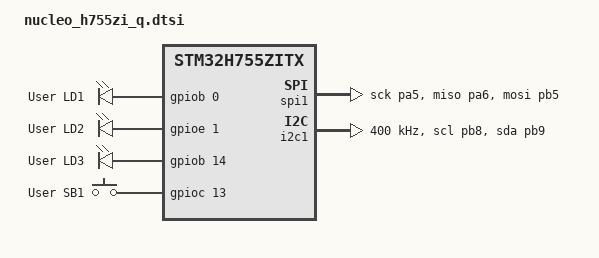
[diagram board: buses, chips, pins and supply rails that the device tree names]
/*
 * Copyright (c) 2024 S&C Electric Company <Michael.Banducci@sandc.com>
 *
 * SPDX-License-Identifier: Apache-2.0
 */

#include <st/h7/stm32h755zitx-pinctrl.dtsi>
#include "arduino_r3_connector.dtsi"
#include <zephyr/dt-bindings/input/input-event-codes.h>

/ {
	leds: leds {
		compatible = "gpio-leds";

		green_led: led_1 {
			gpios = <&gpiob 0 GPIO_ACTIVE_HIGH>;
			label = "User LD1";
		};

		yellow_led: led_2 {
			gpios = <&gpioe 1 GPIO_ACTIVE_HIGH>;
			label = "User LD2";
		};

		red_led: led_3 {
			gpios = <&gpiob 14 GPIO_ACTIVE_HIGH>;
			label = "User LD3";
		};
	};

	gpio_keys {
		compatible = "gpio-keys";

		user_button: button_0 {
			gpios = <&gpioc 13 GPIO_ACTIVE_HIGH>;
			label = "User SB1";
			zephyr,code = <INPUT_KEY_0>;
		};
	};
};

&spi1 {
	pinctrl-0 = <&spi1_sck_pa5 &spi1_miso_pa6 &spi1_mosi_pb5>;
	pinctrl-names = "default";
	cs-gpios = <&gpiod 14 (GPIO_ACTIVE_LOW | GPIO_PULL_UP)>;
};

&i2c1 {
	pinctrl-0 = <&i2c1_scl_pb8 &i2c1_sda_pb9>;
	pinctrl-names = "default";
	scl-gpios = <&gpiob 8 GPIO_ACTIVE_HIGH>;
	sda-gpios = <&gpiob 9 GPIO_ACTIVE_HIGH>;
	clock-frequency = <I2C_BITRATE_FAST>;
};

&rcc {
	d1cpre = <1>;
	hpre = <2>;
	d1ppre = <2>;
	d2ppre1 = <2>;
	d2ppre2 = <2>;
	d3ppre = <2>;
};

&pwr {
	power-supply = "smps-direct";
};

&mailbox {
	status = "okay";
};
